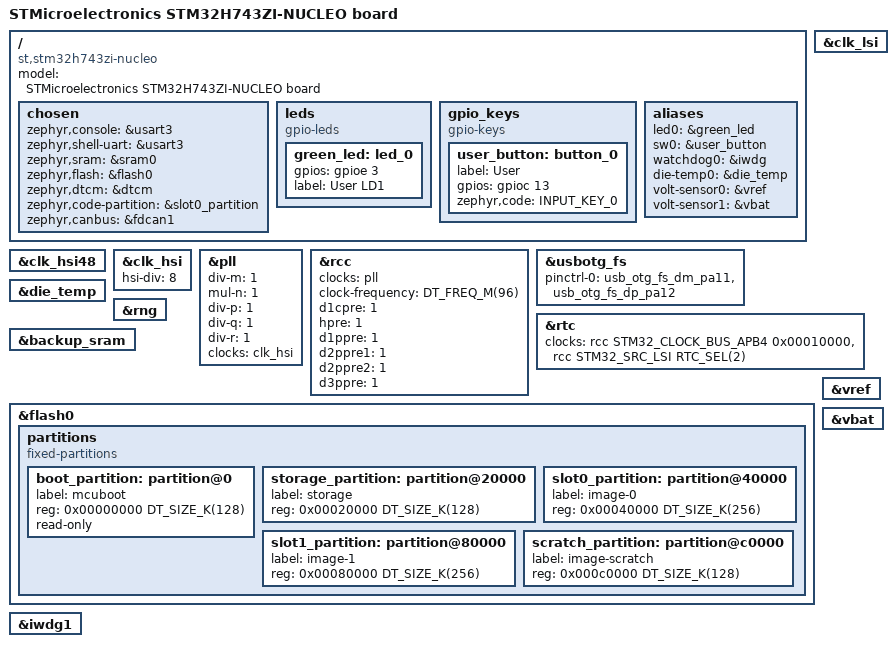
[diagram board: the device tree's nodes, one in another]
/*
 * Copyright (c) 2020 Teslabs Engineering S.L.
 *
 * SPDX-License-Identifier: Apache-2.0
 */

/dts-v1/;
#include <st/h7/stm32h743Xi.dtsi>
#include <st/h7/stm32h743vitx-pinctrl.dtsi>
#include <zephyr/dt-bindings/input/input-event-codes.h>

/ {
    model = "STMicroelectronics STM32H743ZI-NUCLEO board";
    compatible = "st,stm32h743zi-nucleo";

    chosen {
        zephyr,console = &usart3;
        zephyr,shell-uart = &usart3;
        zephyr,sram = &sram0;
        zephyr,flash = &flash0;
        zephyr,dtcm = &dtcm;
        zephyr,code-partition = &slot0_partition;
        zephyr,canbus = &fdcan1;
    };

    leds: leds {
        compatible = "gpio-leds";
        green_led: led_0 {
            gpios = <&gpioe 3 GPIO_ACTIVE_HIGH>;
            label = "User LD1";
        };
    };

    gpio_keys {
        compatible = "gpio-keys";
        user_button: button_0 {
            label = "User";
            gpios = <&gpioc 13 GPIO_ACTIVE_HIGH>;
            zephyr,code = <INPUT_KEY_0>;
        };
    };

    aliases {
        led0 = &green_led;
        sw0 = &user_button;
        watchdog0 = &iwdg;
        die-temp0 = &die_temp;
        volt-sensor0 = &vref;
        volt-sensor1 = &vbat;
    };
};

&clk_lsi {
    status = "okay";
};

&clk_hsi48 {
    status = "okay";
};

&clk_hsi {
    status = "okay";
    hsi-div = <8>;
};


&pll {
    div-m = <1>;
    mul-n = <1>;
    div-p = <1>;
    div-q = <1>;
    div-r = <1>;
    clocks = <&clk_hsi>;
    status = "okay";
};

&rcc {
    clocks = <&pll>;
    clock-frequency = <DT_FREQ_M(96)>;
    d1cpre = <1>;
    hpre = <1>;
    d1ppre = <1>;
    d2ppre1 = <1>;
    d2ppre2 = <1>;
    d3ppre = <1>;
};

zephyr_udc0: &usbotg_fs {
    pinctrl-0 = <&usb_otg_fs_dm_pa11 &usb_otg_fs_dp_pa12>;
    pinctrl-names = "default";
    status = "okay";
};

&rtc {
    clocks = <&rcc STM32_CLOCK_BUS_APB4 0x00010000>,
             <&rcc STM32_SRC_LSI RTC_SEL(2)>;
    status = "okay";
};

&die_temp {
    status = "okay";
};

&rng {
    status = "okay";
};

&backup_sram {
    status = "okay";
};

&flash0 {
    partitions {
        compatible = "fixed-partitions";
        #address-cells = <1>;
        #size-cells = <1>;

        /* 128KB for bootloader */
        boot_partition: partition@0 {
            label = "mcuboot";
            reg = <0x00000000 DT_SIZE_K(128)>;
            read-only;
        };

        /* storage: 128KB for settings */
        storage_partition: partition@20000 {
            label = "storage";
            reg = <0x00020000 DT_SIZE_K(128)>;
        };

        /* application image slot: 256KB */
        slot0_partition: partition@40000 {
            label = "image-0";
            reg = <0x00040000 DT_SIZE_K(256)>;
        };

        /* backup slot: 256KB */
        slot1_partition: partition@80000 {
            label = "image-1";
            reg = <0x00080000 DT_SIZE_K(256)>;
        };

        /* swap slot: 128KB */
        scratch_partition: partition@c0000 {
            label = "image-scratch";
            reg = <0x000c0000 DT_SIZE_K(128)>;
        };

    };
};

&iwdg1 {
    status = "okay";
};

&vref {
    status = "okay";
};

&vbat {
    status = "okay";
};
